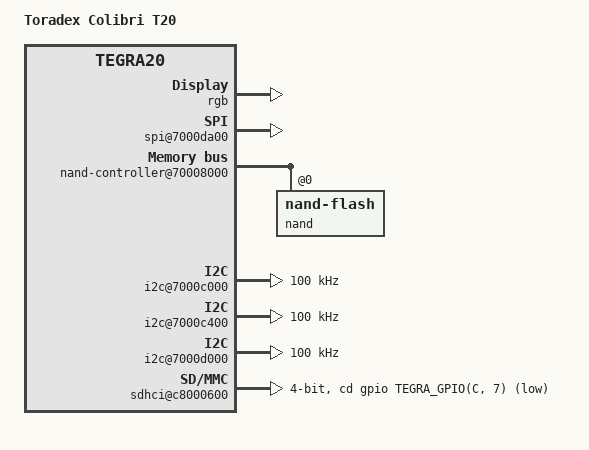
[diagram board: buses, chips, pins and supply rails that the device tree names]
/dts-v1/;

#include "tegra20.dtsi"

/ {
	model = "Toradex Colibri T20";
	compatible = "hostmobility,mx4-mil-se", "toradex,colibri_t20", "nvidia,tegra20";

	signature {
		key-dev {
			required = "image";
			algo = "sha1,rsa2048";
			rsa,r-squared = <0x35b80fc8 0x75ccb6b9 0x06155bcf 0x67544944 0x14ca3ac7 0xb8c9187c 0x5281b510 0x829566ab 0x3cbcca6f 0xcdc27a46 0x2bf6292a 0xe22523d8 0x602ec44c 0x30f2bd3a 0xb00f3f0d 0x41f7f45a 0x00000003 0xe208062a 0x0e6879a4 0x4e64cef0 0xc99aa483 0x338cc666 0xc215cb48 0xb2894f5e 0xa8a71428 0x897a11f1 0x41a91329 0x5b5ba626 0xb36e9e65 0x22a9608b 0xa4fa32be 0x26bc1fce 0x0f07e97e 0x00000008 0x00000003 0x00000003 0x00000003 0x00000002 0x656e0000 0x2f736572 0x00000000 0x73657300 0x2f693263 0x00000003 0x40373030 0x0000000e 0x30633430 0x00000058 0x30000000 0x2f757362 0x00000003 0x40633530 0x0000000e 0x30343030 0x0000006c 0x36303000 0x72790000 0x6d656d6f 0x0000007f 0x00000001 0x00000021 0x65677261 0x6d706c65 0x00000008>;
			rsa,modulus = <0xe3476159 0x2081ed87 0x1896ef25 0xc3db7250 0xf138a8d4 0xa3e8abfd 0x3dad61bb 0x919d508e 0x0e4f4ea4 0x429140fe 0x39a456e5 0x8a357ebf 0xd3c3378c 0x52ece378 0xb2379c4a 0x4c9b3850 0x00000003 0x00010001 0x728dd4f9 0x00000800 0x64657600 0x63686f73 0x0000003d 0x36303030 0x616c6961 0x00000049 0x30000000 0x2f693263 0x00000003 0x40373030 0x0000000e 0x30646130 0x0000005d 0x30000000 0x2f757362 0x00000003 0x40633530 0x00000010 0x38303030 0x6d656d6f 0x00000073 0x00000008 0x00000002 0x00000003 0x69612c74 0x78007369 0x00000003 0x00024000 0x00000000 0x00000043 0x0000008e 0x00000004 0x00000004 0x0000000c 0x04000000 0x00000008 0x00000003 0x00000044 0x0000008e 0x00000002 0x00000008 0x00000003 0x00000045 0x0000008e>;
			rsa,exponent = <0x00000000 0x0000037a>;
			rsa,n0-inverse = <0x728dd4f9>;
			rsa,num-bits = <0x00000800>;
			key-name-hint = "dev";
		};
	};

	chosen {
		stdout-path = &uarta;
	};

	aliases {
		i2c0 = "/i2c@7000d000";
		i2c1 = "/i2c@7000c000";
		i2c2 = "/i2c@7000c400";
		spi0 = "/spi@7000da00";
		usb0 = "/usb@c5008000";
		usb1 = "/usb@c5000000";
		usb2 = "/usb@c5004000";
		sdhci0 = "/sdhci@c8000600";
	};

	host1x {
		status = "okay";
		dc@54200000 {
			status = "okay";
			rgb {
				status = "okay";
				nvidia,panel = <&lcd_panel>;
			};
		};
	};

	spi@7000da00 {
		status = "okay";
		spi-max-frequency = <25000000>;
	};

	usb@c5000000 {
		dr_mode = "otg";
	};

	usb@c5004000 {
		nvidia,phy-reset-gpio = <&gpio TEGRA_GPIO(V, 1) GPIO_ACTIVE_HIGH>;
		nvidia,vbus-gpio = <&gpio TEGRA_GPIO(BB, 1) GPIO_ACTIVE_HIGH>;
	};

	usb@c5008000 {
		nvidia,vbus-gpio = <&gpio TEGRA_GPIO(W, 2) GPIO_ACTIVE_LOW>;
	};

	nand-controller@70008000 {
		nvidia,wp-gpios = <&gpio TEGRA_GPIO(S, 0) GPIO_ACTIVE_HIGH>;
		nvidia,width = <8>;
		nvidia,timing = <15 100 25 80 25 10 15 10 100>;

		nand@0 {
			reg = <0>;
			compatible = "nand-flash";
		};
	};

	/*
	 * GEN1_I2C: I2C_SDA/SCL on SODIMM pin 194/196 (e.g. RTC on carrier
	 * board)
	 */
	i2c@7000c000 {
		status = "okay";
		clock-frequency = <100000>;
	};

	/* GEN2_I2C: unused */

	/* DDC_CLOCK/DATA on X3 pin 15/16 (e.g. display EDID) */
	i2c@7000c400 {
		status = "okay";
		clock-frequency = <100000>;
	};

	/*
	 * PWR_I2C: power I2C to PMIC and temperature sensor
	 */
	i2c@7000d000 {
		status = "okay";
		clock-frequency = <100000>;
	};

	sdhci@c8000600 {
		status = "okay";
		cd-gpios = <&gpio TEGRA_GPIO(C, 7) GPIO_ACTIVE_LOW>;
		bus-width = <4>;
	};

	lcd_panel: panel {
		clock = <25175000>;
		xres = <640>;
		yres = <480>;
		left-margin = <48>;	/* horizontal back porch */
		right-margin = <16>;	/* horizontal front porch */
		hsync-len = <96>;
		lower-margin = <11>;	/* vertical front porch */
		upper-margin = <31>;	/* vertical back porch */
		vsync-len = <2>;
		hsync-active-high;
		vsync-active-high;
		nvidia,bits-per-pixel = <16>;
		nvidia,pwm = <&pwm 0 0>;
		nvidia,backlight-enable-gpios = <&gpio TEGRA_GPIO(T, 4) GPIO_ACTIVE_HIGH>;
		nvidia,panel-timings = <0 0 0 0>;
	};
};
